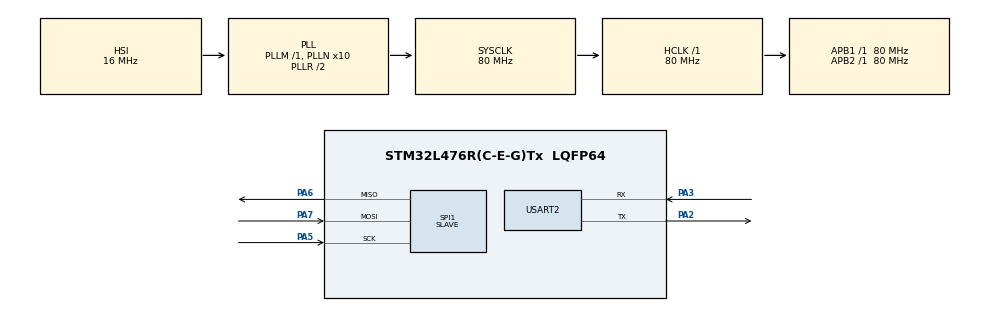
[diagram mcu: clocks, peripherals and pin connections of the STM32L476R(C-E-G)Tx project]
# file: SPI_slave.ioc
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Mcu.Family=STM32L4
Mcu.Name=STM32L476R(C-E-G)Tx
Mcu.Package=LQFP64
NVIC.PriorityGroup=NVIC_PRIORITYGROUP_4
PA2.Mode=Asynchronous
PA2.Signal=USART2_TX
PA3.Mode=Asynchronous
PA3.Signal=USART2_RX
PA4.Signal=SPI1_NSS
PA5.Mode=Full_Duplex_Slave
PA5.Signal=SPI1_SCK
PA6.Mode=Full_Duplex_Slave
PA6.Signal=SPI1_MISO
PA7.Mode=Full_Duplex_Slave
PA7.Signal=SPI1_MOSI
PH0-OSC_IN\ (PH0).Mode=HSE-External-Oscillator
PH0-OSC_IN\ (PH0).Signal=RCC_OSC_IN
PH1-OSC_OUT\ (PH1).Mode=HSE-External-Oscillator
PH1-OSC_OUT\ (PH1).Signal=RCC_OSC_OUT
ProjectManager.HeapSize=0x200
ProjectManager.StackSize=0x400
ProjectManager.TargetToolchain=STM32CubeIDE
RCC.ADCFreq_Value=64000000
RCC.AHBFreq_Value=80000000
RCC.APB1Freq_Value=80000000
RCC.APB1TimFreq_Value=80000000
RCC.APB2Freq_Value=80000000
RCC.APB2TimFreq_Value=80000000
RCC.CortexFreq_Value=80000000
RCC.HCLKFreq_Value=80000000
RCC.HSE_VALUE=8000000
RCC.HSI_VALUE=16000000
RCC.MSI_VALUE=4000000
RCC.PLLN=10
RCC.PLLSourceVirtual=RCC_PLLSOURCE_HSI
RCC.PREFETCH_ENABLE=1
RCC.SYSCLKFreq_VALUE=80000000
RCC.SYSCLKSource=RCC_SYSCLKSOURCE_PLLCLK
RCC.USBFreq_Value=64000000
RCC.VCOOutputFreq_Value=160000000
SPI1.Direction=SPI_DIRECTION_2LINES
SPI1.Mode=SPI_MODE_SLAVE
SPI1.VirtualType=VM_SLAVE
USART2.VirtualMode-Asynchronous=VM_ASYNC
board=NUCLEO-L476RG

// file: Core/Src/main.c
/* USER CODE BEGIN Header */
/**
  ******************************************************************************
  * @file           : main.c
  * @brief          : SPI Slave Code - Echoes back received string frame
  ******************************************************************************
  */
/* USER CODE END Header */
#include "main.h"
#include <stdio.h>
#include <string.h>

SPI_HandleTypeDef hspi1;
UART_HandleTypeDef huart2;

void SystemClock_Config(void);
static void MX_GPIO_Init(void);
static void MX_SPI1_Init(void);
static void MX_USART2_UART_Init(void);

int main(void)
{
  HAL_Init();
  SystemClock_Config();
  MX_GPIO_Init();
  MX_SPI1_Init();
  MX_USART2_UART_Init();

  /* USER CODE BEGIN 2 */
  char slave_rx[3] = {0};
  char slave_tx[3] = "hi"; // Setup the initial payload buffer response
  char uart_buf[100];
  int len;

  len = sprintf(uart_buf, "--- SPI Slave System Initialized & Ready ---\r\n");
  HAL_UART_Transmit(&huart2, (uint8_t*)uart_buf, len, HAL_MAX_DELAY);
  /* USER CODE END 2 */

  /* Infinite loop */
  /* USER CODE BEGIN WHILE */
  while (1)
  {
    // The Slave sits blocking here waiting for the Master to drive the clock line
    if (HAL_SPI_TransmitReceive(&hspi1, (uint8_t*)slave_tx, (uint8_t*)slave_rx, 2, HAL_MAX_DELAY) == HAL_OK)
    {
        // Output received characters to slave console
        len = sprintf(uart_buf, "Slave Received: %s | Echoing Back...\r\n", slave_rx);
        HAL_UART_Transmit(&huart2, (uint8_t*)uart_buf, len, HAL_MAX_DELAY);

        // Copy received data directly to our TX line buffer for the next transaction cycle
        strncpy(slave_tx, slave_rx, 2);
    }
    /* USER CODE END WHILE */
  }
}

static void MX_SPI1_Init(void)
{
  hspi1.Instance = SPI1;
  hspi1.Init.Mode = SPI_MODE_SLAVE;
  hspi1.Init.Direction = SPI_DIRECTION_2LINES;
  hspi1.Init.DataSize = SPI_DATASIZE_8BIT;
  hspi1.Init.CLKPolarity = SPI_POLARITY_LOW;
  hspi1.Init.CLKPhase = SPI_PHASE_1EDGE;
  hspi1.Init.NSS = SPI_NSS_HARD_INPUT; // Hardware managed NSS selection entry
  hspi1.Init.FirstBit = SPI_FIRSTBIT_MSB;
  hspi1.Init.TIMode = SPI_TIMODE_DISABLE;
  hspi1.Init.CRCCalculation = SPI_CRCCALCULATION_DISABLE;
  hspi1.Init.CRCPolynomial = 7;
  hspi1.Init.CRCLength = SPI_CRC_LENGTH_DATASIZE;
  hspi1.Init.NSSPMode = SPI_NSS_PULSE_DISABLE;
  if (HAL_SPI_Init(&hspi1) != HAL_OK)
  {
    Error_Handler();
  }
}

static void MX_USART2_UART_Init(void)
{
  huart2.Instance = USART2;
  huart2.Init.BaudRate = 115200;
  huart2.Init.WordLength = UART_WORDLENGTH_8B;
  huart2.Init.StopBits = UART_STOPBITS_1;
  huart2.Init.Parity = UART_PARITY_NONE;
  huart2.Init.Mode = UART_MODE_TX_RX;
  huart2.Init.HwFlowCtl = UART_HWCONTROL_NONE;
  huart2.Init.OverSampling = UART_OVERSAMPLING_16;
  huart2.Init.OneBitSampling = UART_ONE_BIT_SAMPLE_DISABLE;
  huart2.AdvancedInit.AdvFeatureInit = UART_ADVFEATURE_NO_INIT;
  if (HAL_UART_Init(&huart2) != HAL_OK)
  {
    Error_Handler();
  }
}

static void MX_GPIO_Init(void)
{
  __HAL_RCC_GPIOA_CLK_ENABLE();
  __HAL_RCC_GPIOB_CLK_ENABLE();
}

void SystemClock_Config(void)
{
  RCC_OscInitTypeDef RCC_OscInitStruct = {0};
  RCC_ClkInitTypeDef RCC_ClkInitStruct = {0};

  if (HAL_PWREx_ControlVoltageScaling(PWR_REGULATOR_VOLTAGE_SCALE1) != HAL_OK)
  {
    Error_Handler();
  }
  RCC_OscInitStruct.OscillatorType = RCC_OSCILLATORTYPE_HSI;
  RCC_OscInitStruct.HSIState = RCC_HSI_ON;
  RCC_OscInitStruct.HSICalibrationValue = RCC_HSICALIBRATION_DEFAULT;
  RCC_OscInitStruct.PLL.PLLState = RCC_PLL_ON;
  RCC_OscInitStruct.PLL.PLLSource = RCC_PLLSOURCE_HSI;
  RCC_OscInitStruct.PLL.PLLM = 1;
  RCC_OscInitStruct.PLL.PLLN = 10;
  RCC_OscInitStruct.PLL.PLLP = RCC_PLLP_DIV7;
  RCC_OscInitStruct.PLL.PLLQ = RCC_PLLQ_DIV2;
  RCC_OscInitStruct.PLL.PLLR = RCC_PLLR_DIV2;
  if (HAL_RCC_OscConfig(&RCC_OscInitStruct) != HAL_OK)
  {
    Error_Handler();
  }
  RCC_ClkInitStruct.ClockType = RCC_CLOCKTYPE_HCLK|RCC_CLOCKTYPE_SYSCLK
                              |RCC_CLOCKTYPE_PCLK1|RCC_CLOCKTYPE_PCLK2;
  RCC_ClkInitStruct.SYSCLKSource = RCC_SYSCLKSOURCE_PLLCLK;
  RCC_ClkInitStruct.AHBCLKDivider = RCC_SYSCLK_DIV1;
  RCC_ClkInitStruct.APB1CLKDivider = RCC_HCLK_DIV1;
  RCC_ClkInitStruct.APB2CLKDivider = RCC_HCLK_DIV1;

  if (HAL_RCC_ClockConfig(&RCC_ClkInitStruct, FLASH_LATENCY_4) != HAL_OK)
  {
    Error_Handler();
  }
}

void Error_Handler(void)
{
  __disable_irq();
  while (1)
  {
  }
}
